# ESP32-C61 register map
Vendor: ESPRESSIF SYSTEMS (SHANGHAI) CO., LTD.; Series: ESP32 C-Series; File version: 1
CPU: RV32IMAC r0p0, little endian, no MPU, no FPU, 0 interrupt priority bits
Address unit: 32 bits
Registers are 32-bit, read-write, reset 0x0 unless marked. A register's access mark holds for its fields unless they carry their own. Offsets are from the block's base; [hi:lo] are bit positions; lines under a group give offsets from that group; {n}, {i} and the like mark numbered series.

## TIMG0 — Timer Group 0
Base 0x60008000
Same registers: TIMG1 0x60009000
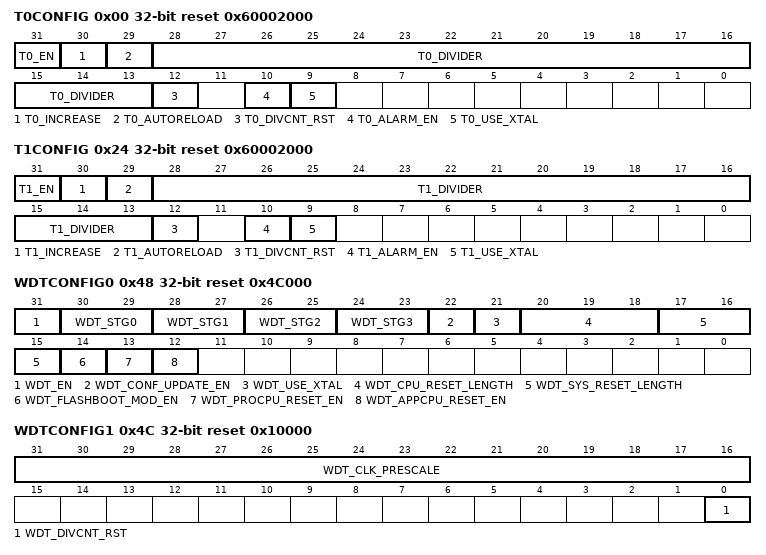
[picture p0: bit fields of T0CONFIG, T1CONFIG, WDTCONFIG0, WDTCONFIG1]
0x00 T0CONFIG access per field reset 0x60002000 — Timer 0 configuration register
  [31] T0_EN rw — Configures whether or not to enable the timer 0 time-base counter. \\ 0: Disable \\ 1: Enable \\
  [30] T0_INCREASE rw — Configures the counting direction of the timer 0 time-base counter. \\ 0: Decrement \\ 1: Increment \\
  [29] T0_AUTORELOAD rw — Configures whether or not to enable the timer 0 auto-reload function at the time of alarm. \\ 0: No effect \\ 1: Enable \\
  [28:13] T0_DIVIDER rw — Represents the timer 0 clock (T0_clk) prescaler value.
  [12] T0_DIVCNT_RST wo — Configures whether or not to reset the timer 0 's clock divider counter. \\ 0: No effect \\ 1: Reset \\
  [10] T0_ALARM_EN rw — Configures whether or not to enable the timer 0 alarm function. This bit will be automatically cleared once an alarm occurs.\\ 0: Disable \\ 1: Enable \\
  [9] T0_USE_XTAL rw — 1: Use XTAL_CLK as the source clock of timer group. 0: Use APB_CLK as the source clock of timer group.
0x04 T0LO ro — Timer 0 current value, low 32 bits
  [31:0] T0_LO — Represents the low 32 bits of the time-base counter of timer 0. Valid only after writing to TIMG_T0UPDATE_REG. \\ Measurement unit: T0_clk \\
0x08 T0HI ro — Timer 0 current value, high 22 bits
  [21:0] T0_HI — Represents the high 22 bits of the time-base counter of timer 0. Valid only after writing to TIMG_T0UPDATE_REG. \\ Measurement unit: T0_clk \\
0x0C T0UPDATE — Write to copy current timer value to TIMGn_T0LO_REG or TIMGn_T0HI_REG
  [31] T0_UPDATE — Configures to latch the counter value. \\ 0: Latch \\ 1: Latch \\
0x10 T0ALARMLO — Timer 0 alarm value, low 32 bits
  [31:0] T0_ALARM_LO — Configures the low 32 bits of timer 0 alarm trigger time-base counter value. Valid only when TIMG_T0_ALARM_EN is 1. \\ Measurement unit: T0_clk \\
0x14 T0ALARMHI — Timer 0 alarm value, high bits
  [21:0] T0_ALARM_HI — Configures the high 22 bits of timer 0 alarm trigger time-base counter value. Valid only when TIMG_T0_ALARM_EN is 1. \\ Measurement unit: T0_clk \\
0x18 T0LOADLO — Timer 0 reload value, low 32 bits
  [31:0] T0_LOAD_LO — Configures low 32 bits of the value that a reload will load onto timer 0 time-base counter. \\ Measurement unit: T0_clk \\
0x1C T0LOADHI — Timer 0 reload value, high 22 bits
  [21:0] T0_LOAD_HI — Configures high 22 bits of the value that a reload will load onto timer 0 time-base counter. \\ Measurement unit: T0_clk \\
0x20 T0LOAD wo — Write to reload timer from TIMG_T0LOADLO_REG or TIMG_T0LOADHI_REG
  [31:0] T0_LOAD — Write any value to trigger a timer 0 time-base counter reload.
0x24 T1CONFIG access per field reset 0x60002000 — Timer 1 configuration register
  [31] T1_EN rw — Configures whether or not to enable the timer 1 time-base counter. \\ 0: Disable \\ 1: Enable \\
  [30] T1_INCREASE rw — Configures the counting direction of the timer 1 time-base counter. \\ 0: Decrement \\ 1: Increment \\
  [29] T1_AUTORELOAD rw — Configures whether or not to enable the timer 1 auto-reload function at the time of alarm. \\ 0: No effect \\ 1: Enable \\
  [28:13] T1_DIVIDER rw — Represents the timer 1 clock (T1_clk) prescaler value.
  [12] T1_DIVCNT_RST wo — Configures whether or not to reset the timer 1 's clock divider counter. \\ 0: No effect \\ 1: Reset \\
  [10] T1_ALARM_EN rw — Configures whether or not to enable the timer 1 alarm function. This bit will be automatically cleared once an alarm occurs.\\ 0: Disable \\ 1: Enable \\
  [9] T1_USE_XTAL rw — 1: Use XTAL_CLK as the source clock of timer group. 0: Use APB_CLK as the source clock of timer group.
0x28 T1LO ro — Timer 1 current value, low 32 bits
  [31:0] T1_LO — Represents the low 32 bits of the time-base counter of timer 1. Valid only after writing to TIMG_T1UPDATE_REG. \\ Measurement unit: T1_clk \\
0x2C T1HI ro — Timer 1 current value, high 22 bits
  [21:0] T1_HI — Represents the high 22 bits of the time-base counter of timer 1. Valid only after writing to TIMG_T1UPDATE_REG. \\ Measurement unit: T1_clk \\
0x30 T1UPDATE — Write to copy current timer value to TIMGn_T0LO_REG or TIMGn_T0HI_REG
  [31] T1_UPDATE — Configures to latch the counter value. \\ 0: Latch \\ 1: Latch \\
0x34 T1ALARMLO — Timer 1 alarm value, low 32 bits
  [31:0] T1_ALARM_LO — Configures the low 32 bits of timer 1 alarm trigger time-base counter value. Valid only when TIMG_T1_ALARM_EN is 1. \\ Measurement unit: T1_clk \\
0x38 T1ALARMHI — Timer 1 alarm value, high bits
  [21:0] T1_ALARM_HI — Configures the high 22 bits of timer 1 alarm trigger time-base counter value. Valid only when TIMG_T1_ALARM_EN is 1. \\ Measurement unit: T1_clk \\
0x3C T1LOADLO — Timer 1 reload value, low 32 bits
  [31:0] T1_LOAD_LO — Configures low 32 bits of the value that a reload will load onto timer 1 time-base counter. \\ Measurement unit: T1_clk \\
0x40 T1LOADHI — Timer 1 reload value, high 22 bits
  [21:0] T1_LOAD_HI — Configures high 22 bits of the value that a reload will load onto timer 1 time-base counter. \\ Measurement unit: T1_clk \\
0x44 T1LOAD wo — Write to reload timer from TIMG_T1LOADLO_REG or TIMG_T1LOADHI_REG
  [31:0] T1_LOAD — Write any value to trigger a timer 1 time-base counter reload.
0x48 WDTCONFIG0 access per field reset 0x4C000 — Watchdog timer configuration register
  [31] WDT_EN rw — Configures whether or not to enable the MWDT. Valid only when write protection is disabled. \\ 0: Disable \\ 1: Enable \\
  [30:29] WDT_STG0 rw — Configures the timeout action of stage 0. Valid only when write protection is disabled. \\ 0: No effect \\ 1: Interrupt \\ 2: Reset CPU \\ 3: Reset system \\
  [28:27] WDT_STG1 rw — Configures the timeout action of stage 1. See details in TIMG_WDT_STG0. Valid only when write protection is disabled.
  [26:25] WDT_STG2 rw — Configures the timeout action of stage 2. See details in TIMG_WDT_STG0. Valid only when write protection is disabled.
  [24:23] WDT_STG3 rw — Configures the timeout action of stage 3. See details in TIMG_WDT_STG0. Valid only when write protection is disabled.
  [22] WDT_CONF_UPDATE_EN wo — Configures to update the WDT configuration registers.\\ 0: No effect \\ 1: Update \\
  [21] WDT_USE_XTAL rw — choose WDT clock:0-apb_clk, 1-xtal_clk.
  [20:18] WDT_CPU_RESET_LENGTH rw — Configures the CPU reset signal length. Valid only when write protection is disabled.\\ Measurement unit: mwdt_clk \\ \begin{multicols}{2} 0: 8 \\ 1: 16 \\ 2: 24 \\ 3: 32 \\ 4: 40 \\ 5: 64 \\ 6: 128 \\ 7: 256 \\ \end{multicols}
  [17:15] WDT_SYS_RESET_LENGTH rw — Configures the system reset signal length. Valid only when write protection is disabled. \\ Measurement unit: mwdt_clk \begin{multicols}{2} 0: 8 \\ 1: 16 \\ 2: 24 \\ 3: 32 \\ 4: 40 \\ 5: 64 \\ 6: 128 \\ 7: 256 \\ \end{multicols}
  [14] WDT_FLASHBOOT_MOD_EN rw — Configures whether to enable flash boot protection.\\ 0: Disable \\ 1: Enable \\
  [13] WDT_PROCPU_RESET_EN rw — Configures whether to mask the CPU reset generated by MWDT. Valid only when write protection is disabled. \\ 0: Mask \\ 1: Unmask \\
  [12] WDT_APPCPU_RESET_EN rw — Configures whether to mask the CPU reset generated by MWDT. Valid only when write protection is disabled. \\ 0: Mask \\ 1: Unmask \\
0x4C WDTCONFIG1 access per field reset 0x10000 — Watchdog timer prescaler register
  [31:16] WDT_CLK_PRESCALE rw — Configures MWDT clock prescaler value. Valid only when write protection is disabled. \\ MWDT clock period = MWDT's clock source period * TIMG_WDT_CLK_PRESCALE. \\
  [0] WDT_DIVCNT_RST wo — Configures whether to reset WDT 's clock divider counter. \\ 0: No effect \\ 1: Reset \\
0x50 WDTCONFIG2 reset 0x18CBA80 — Watchdog timer stage 0 timeout value
  [31:0] WDT_STG0_HOLD — Configures the stage 0 timeout value. Valid only when write protection is disabled. \\ Measurement unit: mwdt_clk \\
0x54 WDTCONFIG3 reset 0x7FFFFFF — Watchdog timer stage 1 timeout value
  [31:0] WDT_STG1_HOLD — Configures the stage 1 timeout value. Valid only when write protection is disabled.\\ Measurement unit: mwdt_clk \\
0x58 WDTCONFIG4 reset 0xFFFFF — Watchdog timer stage 2 timeout value
  [31:0] WDT_STG2_HOLD — Configures the stage 2 timeout value. Valid only when write protection is disabled. \\ Measurement unit: mwdt_clk \\
0x5C WDTCONFIG5 reset 0xFFFFF — Watchdog timer stage 3 timeout value
  [31:0] WDT_STG3_HOLD — Configures the stage 3 timeout value. Valid only when write protection is disabled. \\ Measurement unit: mwdt_clk \\
0x60 WDTFEED wo — Write to feed the watchdog timer
  [31:0] WDT_FEED — Write any value to feed the MWDT. Valid only when write protection is disabled.
0x64 WDTWPROTECT reset 0x50D83AA1 — Watchdog write protect register
  [31:0] WDT_WKEY — Configures a different value than its reset value to enable write protection.
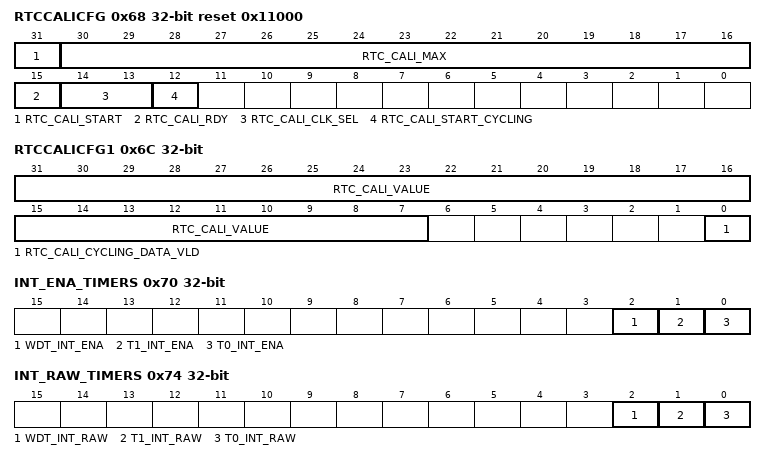
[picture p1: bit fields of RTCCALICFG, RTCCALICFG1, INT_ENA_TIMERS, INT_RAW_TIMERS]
0x68 RTCCALICFG access per field reset 0x11000 — RTC frequency calculation configuration register 0
  [31] RTC_CALI_START rw — Configures whether to enable one-shot frequency calculation. \\ 0: Disable \\ 1: Enable \\
  [30:16] RTC_CALI_MAX rw — Configures the time to calculate RTC slow clock's frequency. \\ Measurement unit: XTAL_CLK \\
  [15] RTC_CALI_RDY ro — Represents whether one-shot frequency calculation is done.\\ 0: Not done \\ 1: Done \\
  [14:13] RTC_CALI_CLK_SEL rw — Configures to select the clock to be calibrated\\ 0: RTC_SLOW_CLK\\ 1: RC_FAST_DIV_CLK\\ 2: XTAL32K_CLK\\
  [12] RTC_CALI_START_CYCLING rw — Configures the frequency calculation mode. \\ 0: one-shot frequency calculation \\ 1: periodic frequency calculation \\
0x6C RTCCALICFG1 ro — RTC frequency calculation configuration register 1
  [31:7] RTC_CALI_VALUE — Represents the value countered by XTAL_CLK when one-shot or periodic frequency calculation is done. It is used to calculate RTC slow clock's frequency.
  [0] RTC_CALI_CYCLING_DATA_VLD — Represents whether periodic frequency calculation is done. \\ 0: Not done \\ 1: Done \\
0x70 INT_ENA_TIMERS — Interrupt enable bits
  [2] WDT_INT_ENA — Write 1 to enable the TIMG_WDT_INT interrupt.
  [1] T1_INT_ENA — Write 1 to enable the TIMG_T1_INT interrupt.
  [0] T0_INT_ENA — Write 1 to enable the TIMG_T0_INT interrupt.
0x74 INT_RAW_TIMERS ro — Raw interrupt status
  [2] WDT_INT_RAW — The raw interrupt status bit of the TIMG_WDT_INT interrupt.
  [1] T1_INT_RAW — The raw interrupt status bit of the TIMG_T1_INT interrupt.
  [0] T0_INT_RAW — The raw interrupt status bit of the TIMG_T0_INT interrupt.
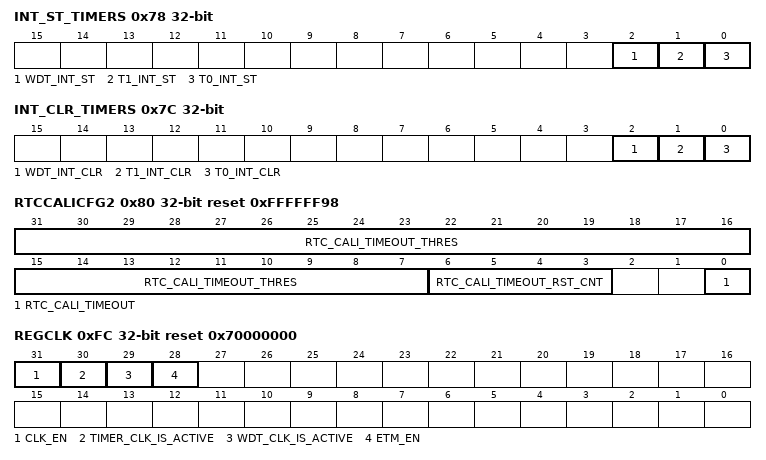
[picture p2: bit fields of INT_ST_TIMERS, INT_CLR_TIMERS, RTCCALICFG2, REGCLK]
0x78 INT_ST_TIMERS ro — Masked interrupt status
  [2] WDT_INT_ST — The masked interrupt status bit of the TIMG_WDT_INT interrupt.
  [1] T1_INT_ST — The masked interrupt status bit of the TIMG_T1_INT interrupt.
  [0] T0_INT_ST — The masked interrupt status bit of the TIMG_T0_INT interrupt.
0x7C INT_CLR_TIMERS wo — Interrupt clear bits
  [2] WDT_INT_CLR — Write 1 to clear the TIMG_WDT_INT interrupt.
  [1] T1_INT_CLR — Write 1 to clear the TIMG_T1_INT interrupt.
  [0] T0_INT_CLR — Write 1 to clear the TIMG_T0_INT interrupt.
0x80 RTCCALICFG2 access per field reset 0xFFFFFF98 — RTC frequency calculation configuration register 2
  [31:7] RTC_CALI_TIMEOUT_THRES rw — Configures the threshold value for the RTC frequency calculation timer. If the timer's value exceeds this threshold, a timeout is triggered.\\ Measurement unit: XTAL_CLK \\
  [6:3] RTC_CALI_TIMEOUT_RST_CNT rw — Configures the cycles that reset frequency calculation timeout. \\ Measurement unit: XTAL_CLK \\
  [0] RTC_CALI_TIMEOUT ro — Represents whether RTC frequency calculation is timeout. \\ 0: No timeout \\ 1: Timeout \\
0xF8 NTIMERS_DATE reset 0x2209142 — Timer version control register
  [27:0] NTIMGS_DATE — Version control register
0xFC REGCLK reset 0x70000000 — Timer group clock gate register
  [31] CLK_EN — Configures whether to enable gate clock signal for registers. \\ 0: Force clock on for registers \\ 1: Support clock only when registers are read or written to by software. \\
  [30] TIMER_CLK_IS_ACTIVE — Configures whether to enable Timer 30's clock.\\ 0: Disable \\ 1: Enable \\
  [29] WDT_CLK_IS_ACTIVE — Configures whether to enable WDT's clock. \\ 0: Disable \\ 1: Enable \\
  [28] ETM_EN — Configures whether to enable timer's ETM task and event. \\ 0: Disable \\ 1: Enable \\
